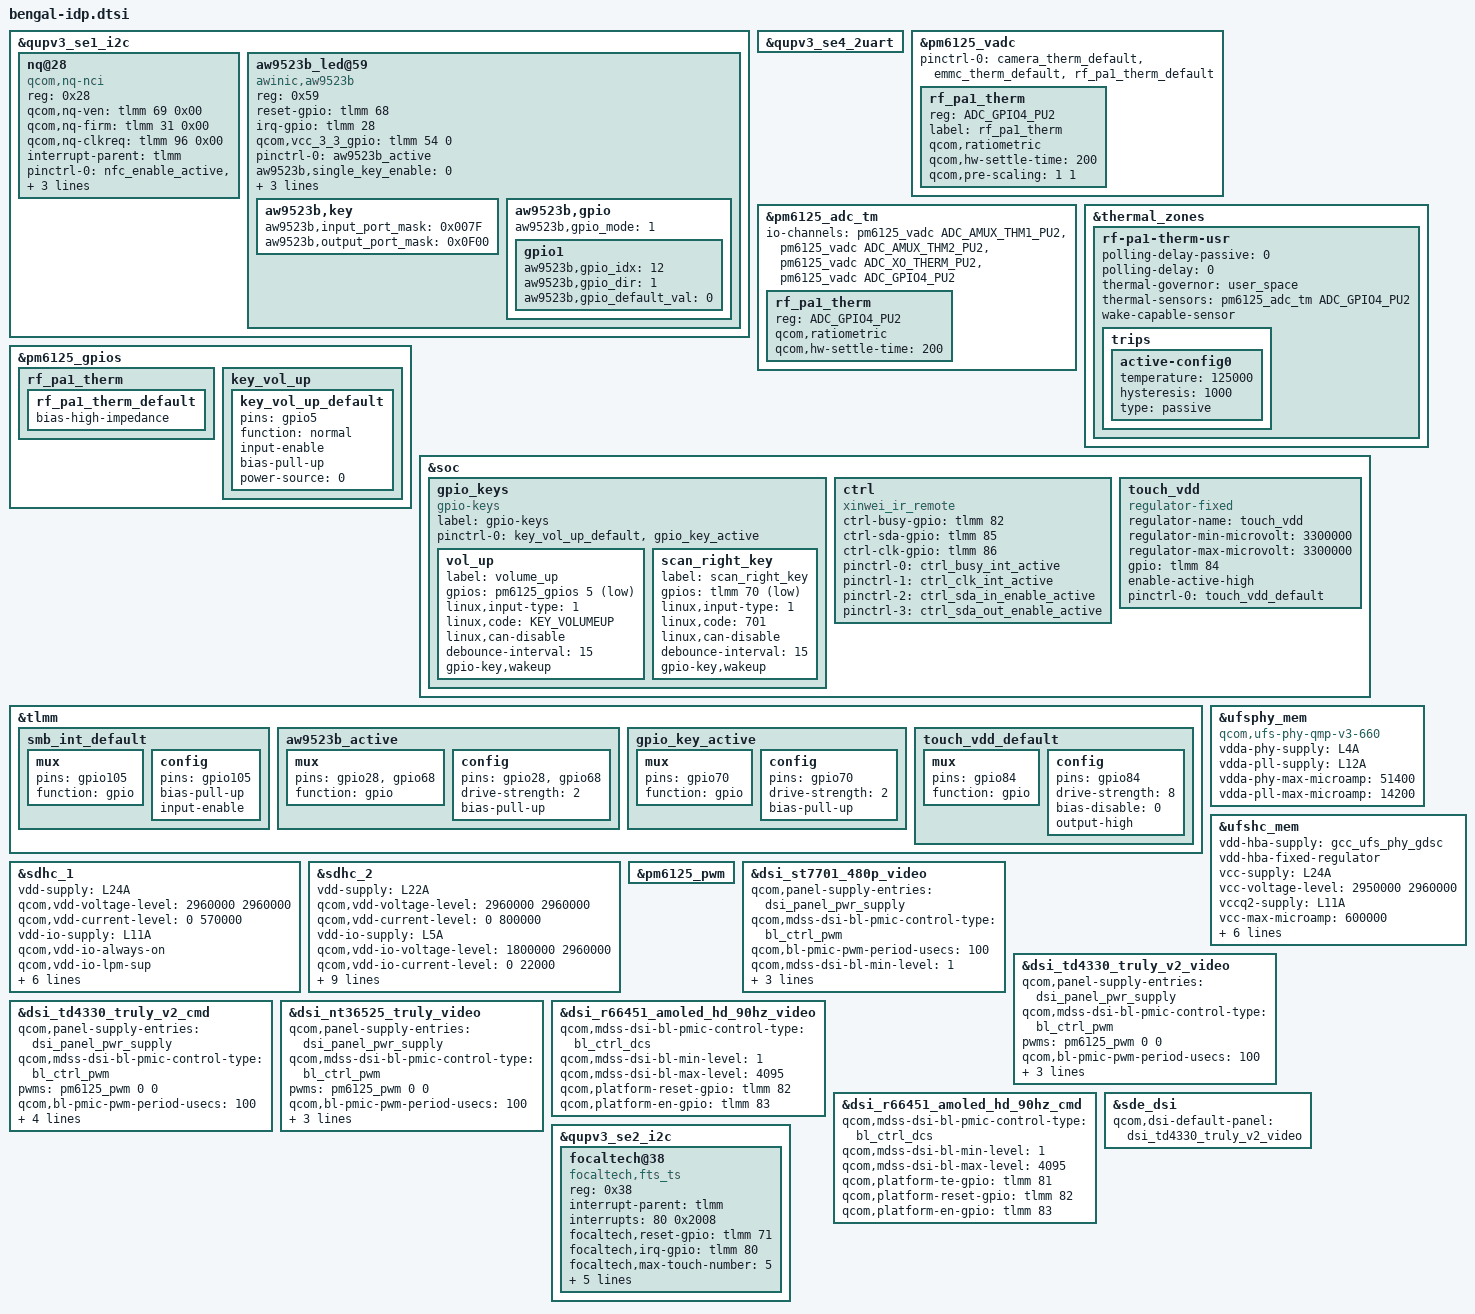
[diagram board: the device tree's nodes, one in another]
#include <dt-bindings/gpio/gpio.h>
#include <dt-bindings/iio/qcom,spmi-vadc.h>
#include <dt-bindings/input/input.h>
#include "bengal-audio-overlay.dtsi"
#include "bengal-thermal-overlay.dtsi"
#include "bengal-sde-display.dtsi"
#include "camera/bengal-camera-sensor-idp.dtsi"

&qupv3_se1_i2c {
	status = "ok";
	#include "smb1355.dtsi"
};

&qupv3_se4_2uart {
	status = "ok";
};

&pm6125_vadc {
	pinctrl-0 = <&camera_therm_default &emmc_therm_default &rf_pa1_therm_default>;

	rf_pa1_therm {
		reg = <ADC_GPIO4_PU2>;
		label = "rf_pa1_therm";
		qcom,ratiometric;
		qcom,hw-settle-time = <200>;
		qcom,pre-scaling = <1 1>;
	};
};

&pm6125_adc_tm {
	io-channels = <&pm6125_vadc ADC_AMUX_THM1_PU2>,
			<&pm6125_vadc ADC_AMUX_THM2_PU2>,
			<&pm6125_vadc ADC_XO_THERM_PU2>,
			<&pm6125_vadc ADC_GPIO4_PU2>;

	rf_pa1_therm {
		reg = <ADC_GPIO4_PU2>;
		qcom,ratiometric;
		qcom,hw-settle-time = <200>;
	};
};

&thermal_zones {
	rf-pa1-therm-usr {
		polling-delay-passive = <0>;
		polling-delay = <0>;
		thermal-governor = "user_space";
		thermal-sensors = <&pm6125_adc_tm ADC_GPIO4_PU2>;
		wake-capable-sensor;
		trips {
			active-config0 {
				temperature = <125000>;
				hysteresis = <1000>;
				type = "passive";
			};
		};
	};
};

&pm6125_gpios {

	rf_pa1_therm {
		rf_pa1_therm_default: rf_pa1_therm_default {
			//pins = "gpio7";  //wanghuantong close other gpio7
			 bias-high-impedance;
		};
	};

	key_vol_up {
		key_vol_up_default: key_vol_up_default {
			pins = "gpio5";
			function = "normal";
			input-enable;
			bias-pull-up;
			power-source = <0>;
		};
	};
};

&soc {
	gpio_keys {
		compatible = "gpio-keys";
		label = "gpio-keys";

		pinctrl-names = "default";
		pinctrl-0 = <&key_vol_up_default &gpio_key_active>;

		vol_up {
			label = "volume_up";
			gpios = <&pm6125_gpios 5 GPIO_ACTIVE_LOW>;
			linux,input-type = <1>;
			linux,code = <KEY_VOLUMEUP>;
			linux,can-disable;
			debounce-interval = <15>;
			gpio-key,wakeup;
		};
		 scan_right_key {       //wanghuantong add custom_key start
                          label = "scan_right_key";
                          gpios = <&tlmm 70 GPIO_ACTIVE_LOW>;
                          linux,input-type = <1>;
                          linux,code = <701>; 
                          linux,can-disable;
                          debounce-interval = <15>;
                          gpio-key,wakeup;
                  };//end
      };
      ctrl{//likefei add ifrared function et4007
		status="ok";
		compatible = "xinwei_ir_remote";
		ctrl-busy-gpio = <&tlmm 82 0>;
		ctrl-sda-gpio = <&tlmm 85 0>;
		ctrl-clk-gpio = <&tlmm 86 0>;
		pinctrl-names ="ctrl_busy_int_active","ctrl_clk_int_active",
		"ctrl_sda_in_enable_active","ctrl_sda_out_enable_active";
		pinctrl-0 = <&ctrl_busy_int_active>;
		pinctrl-1 = <&ctrl_clk_int_active>;
		pinctrl-2 = <&ctrl_sda_in_enable_active>;
		pinctrl-3 = <&ctrl_sda_out_enable_active>;
	};
	
};

&qupv3_se1_i2c {
	status = "ok";
	#address-cells = <1>;
	#size-cells = <0>;
	nq@28 {
		compatible = "qcom,nq-nci";
		reg = <0x28>;
		//qcom,nq-irq = <&tlmm 70 0x00>;
		qcom,nq-ven = <&tlmm 69 0x00>;
		qcom,nq-firm = <&tlmm 31 0x00>;
		qcom,nq-clkreq = <&tlmm 96 0x00>;//likefei conflict change 86 to 96
		interrupt-parent = <&tlmm>;
		//interrupts = <70 0>;
		interrupt-names = "nfc_irq";
		pinctrl-names = "nfc_active", "nfc_suspend";
		pinctrl-0 = </*&nfc_int_active*/ &nfc_enable_active
				&nfc_clk_req_active>;
		pinctrl-1 = </*&nfc_int_suspend*/ &nfc_enable_suspend
				&nfc_clk_req_suspend>;
	};
		aw9523b_led@59 {
		compatible = "awinic,aw9523b";
		reg = <0x59>; //addr
		reset-gpio = <&tlmm 68 0>; //rst gpio
		irq-gpio = <&tlmm 28 0>; //irq gpio
		qcom,vcc_3_3_gpio = <&tlmm 54 0>;
//		aw9523b_power-supply = <&pm8909_l6>; //VCC
      pinctrl-names = "default";
		pinctrl-0 = <&aw9523b_active>;
		status = "ok";
		aw9523b,single_key_enable = <0>; //enable single key function, 0 to disable
		aw9523b,matrix_key_enable = <1>; //enable matrix key function, 0 to disable
		aw9523b,led_enable = <0>; //enabel led function, 0 to disable
		aw9523b,gpio_enable = <1>; //enable gpio function, 0 to disable
		aw9523b,key{
			aw9523b,input_port_mask = <0x007F>; // 0000 0000 0111 1111 Identifies the pin port for the input. here: P0_0-P0_6
			aw9523b,output_port_mask = <0x0F00>; //0000 1111 0000 0000 Identifies the pin port for the output here: P1_0-P1_3
		};
		aw9523b,gpio{
			aw9523b,gpio_mode = <1>;
			gpio1{
				aw9523b,gpio_idx = <12>; // The specific port identifier used, This is used here:P1_4
				aw9523b,gpio_dir = <1>; // The specific port work in output(1) or input(0)
				aw9523b,gpio_default_val = <0>;
			};
	
};
};
};
&tlmm {
	smb_int_default: smb_int_default {
		mux {
			pins = "gpio105";
			function = "gpio";
		};

		config {
			pins = "gpio105";
			bias-pull-up;
			input-enable;
		};
	};
};
&tlmm{
aw9523b_active: aw9523b_active {        //wanghuantong add aw9523b
                               mux {
                                       pins = "gpio28", "gpio68";
                                       function = "gpio";
                               };

                               config {
                                       pins = "gpio28", "gpio68";
                                       drive-strength = <2>;
                                       bias-pull-up;
                               };
                       };
                       gpio_key_active: gpio_key_active {     //wanghuantong add custom_key start
                               mux {
                                       pins = "gpio70";
                                       function = "gpio";
                               };

                               config {
                                       pins = "gpio70";
                                      drive-strength = <2>;
                                       bias-pull-up;
                               };
                       };  //end
      };
&sdhc_1 {
	vdd-supply = <&L24A>;
	qcom,vdd-voltage-level = <2960000 2960000>;
	qcom,vdd-current-level = <0 570000>;

	vdd-io-supply = <&L11A>;
	qcom,vdd-io-always-on;
	qcom,vdd-io-lpm-sup;
	qcom,vdd-io-voltage-level = <1800000 1800000>;
	qcom,vdd-io-current-level = <0 325000>;

	pinctrl-names = "active", "sleep";
	pinctrl-0 = <&sdc1_clk_on &sdc1_cmd_on &sdc1_data_on
					&sdc1_rclk_on>;
	pinctrl-1 = <&sdc1_clk_off &sdc1_cmd_off &sdc1_data_off
					&sdc1_rclk_off>;

	status = "ok";
};

&sdhc_2 {
	vdd-supply = <&L22A>;
	qcom,vdd-voltage-level = <2960000 2960000>;
	qcom,vdd-current-level = <0 800000>;

	vdd-io-supply = <&L5A>;
	qcom,vdd-io-voltage-level = <1800000 2960000>;
	qcom,vdd-io-current-level = <0 22000>;

	vdd-io-bias-supply = <&L7A>;
	qcom,vdd-io-bias-voltage-level = <1256000 1256000>;
	qcom,vdd-io-bias-current-level = <0 6000>;

	pinctrl-names = "active", "sleep";
	pinctrl-0 = <&sdc2_clk_on  &sdc2_cmd_on &sdc2_data_on &sdc2_cd_on>;
	pinctrl-1 = <&sdc2_clk_off &sdc2_cmd_off &sdc2_data_off &sdc2_cd_off>;

	cd-gpios = <&tlmm 88 GPIO_ACTIVE_HIGH>;//hujing for sd card 20220903

	status = "ok";
};

&ufsphy_mem {
	compatible = "qcom,ufs-phy-qmp-v3-660";

	vdda-phy-supply = <&L4A>; /* 0.9v */
	vdda-pll-supply = <&L12A>; /* 1.8v */
	vdda-phy-max-microamp = <51400>;
	vdda-pll-max-microamp = <14200>;

	status = "ok";
};

&ufshc_mem {
	vdd-hba-supply = <&gcc_ufs_phy_gdsc>;
	vdd-hba-fixed-regulator;
	vcc-supply = <&L24A>;
	vcc-voltage-level = <2950000 2960000>;
	vccq2-supply = <&L11A>;
	vcc-max-microamp = <600000>;
	vccq2-max-microamp = <600000>;
	vccq2-pwr-collapse-sup;

	qcom,vddp-ref-clk-supply = <&L18A>;
	qcom,vddp-ref-clk-max-microamp = <100>;
	qcom,vddp-ref-clk-min-uV = <1232000>;
	qcom,vddp-ref-clk-max-uV = <1232000>;

	status = "ok";
};

&pm6125_pwm {
	status = "ok";
};
/*liushuaibo add st7701 for lcd start 20220802*/
&dsi_st7701_480p_video {
	qcom,panel-supply-entries = <&dsi_panel_pwr_supply>;
	qcom,mdss-dsi-bl-pmic-control-type = "bl_ctrl_pwm";
	//pwms = <&pm6125_pwm 0 0>;
	qcom,bl-pmic-pwm-period-usecs = <100>;
	qcom,mdss-dsi-bl-min-level = <1>;
	qcom,mdss-dsi-bl-max-level = <4095>;
	qcom,platform-reset-gpio = <&tlmm 16 0>;
	qcom,platform-lcd-vdd-en-gpio = <&tlmm 67 0>;
};
/*liushuaibo add st7701 for lcd end 20220802*/

&dsi_td4330_truly_v2_video {
	qcom,panel-supply-entries = <&dsi_panel_pwr_supply>;
	qcom,mdss-dsi-bl-pmic-control-type = "bl_ctrl_pwm";
	pwms = <&pm6125_pwm 0 0>;
	qcom,bl-pmic-pwm-period-usecs = <100>;
	qcom,mdss-dsi-bl-min-level = <1>;
	qcom,mdss-dsi-bl-max-level = <4095>;
	qcom,platform-reset-gpio = <&tlmm 82 0>;
};

&dsi_td4330_truly_v2_cmd {
	qcom,panel-supply-entries = <&dsi_panel_pwr_supply>;
	qcom,mdss-dsi-bl-pmic-control-type = "bl_ctrl_pwm";
	pwms = <&pm6125_pwm 0 0>;
	qcom,bl-pmic-pwm-period-usecs = <100>;
	qcom,mdss-dsi-bl-min-level = <1>;
	qcom,mdss-dsi-bl-max-level = <4095>;
	qcom,platform-te-gpio = <&tlmm 81 0>;
	qcom,platform-reset-gpio = <&tlmm 82 0>;
};

&dsi_nt36525_truly_video {
	qcom,panel-supply-entries = <&dsi_panel_pwr_supply>;
	qcom,mdss-dsi-bl-pmic-control-type = "bl_ctrl_pwm";
	pwms = <&pm6125_pwm 0 0>;
	qcom,bl-pmic-pwm-period-usecs = <100>;
	qcom,mdss-dsi-bl-min-level = <1>;
	qcom,mdss-dsi-bl-max-level = <4095>;
	qcom,platform-reset-gpio = <&tlmm 82 0>;
};

&dsi_r66451_amoled_hd_90hz_video {
	qcom,mdss-dsi-bl-pmic-control-type = "bl_ctrl_dcs";
	qcom,mdss-dsi-bl-min-level = <1>;
	qcom,mdss-dsi-bl-max-level = <4095>;
	qcom,platform-reset-gpio = <&tlmm 82 0>;
	qcom,platform-en-gpio = <&tlmm 83 0>;
};

&dsi_r66451_amoled_hd_90hz_cmd {
	qcom,mdss-dsi-bl-pmic-control-type = "bl_ctrl_dcs";
	qcom,mdss-dsi-bl-min-level = <1>;
	qcom,mdss-dsi-bl-max-level = <4095>;
	qcom,platform-te-gpio = <&tlmm 81 0>;
	qcom,platform-reset-gpio = <&tlmm 82 0>;
	qcom,platform-en-gpio = <&tlmm 83 0>;
};

&sde_dsi {
	qcom,dsi-default-panel = <&dsi_td4330_truly_v2_video>;
};

&tlmm {
	touch_vdd_default: touch_vdd_default {
		mux {
			pins = "gpio84";
			function = "gpio";
		};

		config {
			pins = "gpio84";
			drive-strength = <8>;
			bias-disable = <0>;
			output-high;
		};
	};
};

&soc {
	touch_vdd: touch_vdd {
			compatible = "regulator-fixed";
			regulator-name = "touch_vdd";
			regulator-min-microvolt = <3300000>;
			regulator-max-microvolt = <3300000>;
			gpio = <&tlmm 84 GPIO_ACTIVE_HIGH>;
			enable-active-high;
			pinctrl-names = "default";
			pinctrl-0 = <&touch_vdd_default>;
	};
};


&qupv3_se2_i2c {
	status = "okay";
	//qcom,i2c-touch-active="synaptics,tcm-i2c";

	focaltech@38 {
		compatible = "focaltech,fts_ts";
		reg = <0x38>;
		interrupt-parent = <&tlmm>;
		interrupts = <80 0x2008>;
		focaltech,reset-gpio = <&tlmm 71 0x00>;
		focaltech,irq-gpio = <&tlmm 80 0x2008>;
		//focaltech,vdd-gpio = <&tlmm 67 0x00>;
		focaltech,max-touch-number = <5>;
		focaltech,display-coords = <0 0 480 800>;

		//vdd-supply = <&touch_vdd>;

		pinctrl-names = "pmx_ts_active","pmx_ts_suspend",
			"pmx_ts_release";
		pinctrl-0 = <&ts_int_active &ts_reset_active>;
		pinctrl-1 = <&ts_int_suspend &ts_reset_suspend>;
		pinctrl-2 = <&ts_release>;

		panel = <&dsi_st7701_480p_video>;
	};
};
